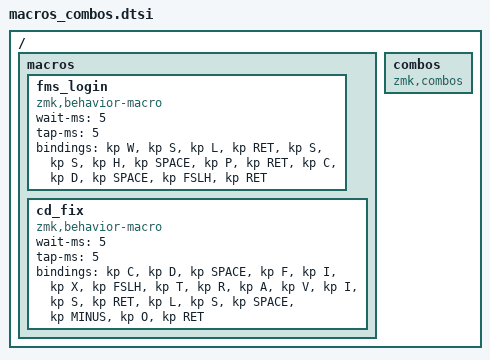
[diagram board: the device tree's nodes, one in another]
/*
 * The four password macros are NOT here. They live in secrets.dtsi, which is
 * a placeholder in git and gets overwritten from the MACROS_COMBOS_DTSI
 * Actions secret at build time.
 */
#include "secrets.dtsi"

/ {
    macros {
        fms_login: fms_login {
            compatible = "zmk,behavior-macro";
            #binding-cells = <0>;
            wait-ms = <5>;
            tap-ms = <5>;
            bindings =
                <&kp W &kp S &kp L &kp RET>,
                <&kp S &kp S &kp H &kp SPACE &kp P &kp RET>,
                <&kp C &kp D &kp SPACE &kp FSLH &kp RET>;
        };

        cd_fix: cd_fix {
            compatible = "zmk,behavior-macro";
            #binding-cells = <0>;
            wait-ms = <5>;
            tap-ms = <5>;
            bindings =
                <&kp C &kp D &kp SPACE &kp F &kp I &kp X &kp FSLH &kp T &kp R &kp A &kp V &kp I &kp S &kp RET>,
                <&kp L &kp S &kp SPACE &kp MINUS &kp O &kp RET>;
        };
    };

    combos {
        compatible = "zmk,combos";
    };
};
